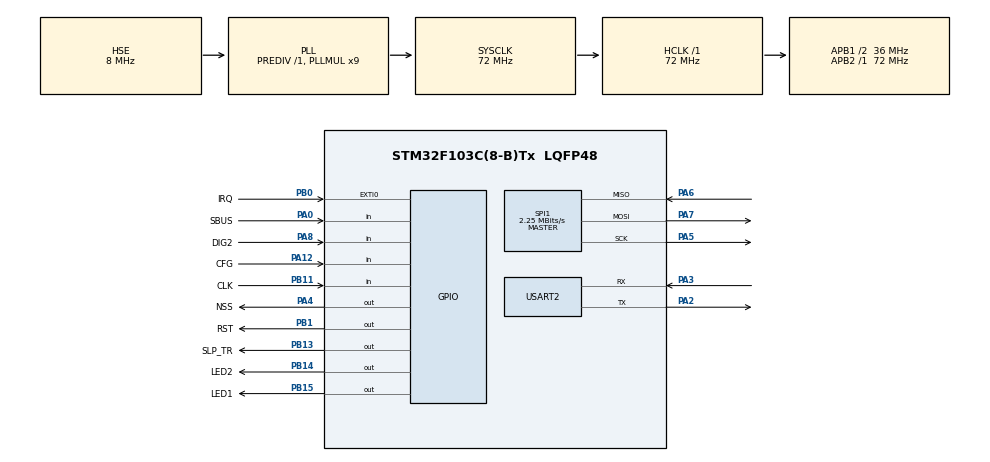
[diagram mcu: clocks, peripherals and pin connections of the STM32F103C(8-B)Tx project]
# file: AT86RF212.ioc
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Mcu.Family=STM32F1
Mcu.Name=STM32F103C(8-B)Tx
Mcu.Package=LQFP48
NVIC.PriorityGroup=NVIC_PRIORITYGROUP_4
NVIC.USART2_IRQn=true\:0\:0\:false\:false\:true\:true\:true
PA0-WKUP.GPIO_Label=SBUS
PA0-WKUP.GPIO_PuPd=GPIO_PULLUP
PA0-WKUP.Signal=GPIO_Input
PA12.GPIO_Label=CFG
PA12.GPIO_PuPd=GPIO_PULLUP
PA12.Signal=GPIO_Input
PA13.Mode=Serial_Wire
PA13.Signal=SYS_JTMS-SWDIO
PA14.Mode=Serial_Wire
PA14.Signal=SYS_JTCK-SWCLK
PA2.Mode=Asynchronous
PA2.Signal=USART2_TX
PA3.Mode=Asynchronous
PA3.Signal=USART2_RX
PA4.GPIO_Label=NSS
PA4.GPIO_PuPd=GPIO_PULLUP
PA4.GPIO_Speed=GPIO_SPEED_FREQ_MEDIUM
PA4.PinState=GPIO_PIN_SET
PA4.Signal=GPIO_Output
PA5.Mode=Full_Duplex_Master
PA5.Signal=SPI1_SCK
PA6.Mode=Full_Duplex_Master
PA6.Signal=SPI1_MISO
PA7.Mode=Full_Duplex_Master
PA7.Signal=SPI1_MOSI
PA8.GPIO_Label=DIG2
PA8.Signal=GPIO_Input
PB0.GPIO_Label=IRQ
PB0.GPIO_PuPd=GPIO_PULLUP
PB0.Signal=GPXTI0
PB1.GPIO_Label=RST
PB1.GPIO_ModeDefaultOutputPP=GPIO_MODE_OUTPUT_PP
PB1.GPIO_PuPd=GPIO_PULLUP
PB1.PinState=GPIO_PIN_SET
PB1.Signal=GPIO_Output
PB11.GPIO_Label=CLK
PB11.GPIO_PuPd=GPIO_PULLUP
PB11.Signal=GPIO_Input
PB13.GPIO_Label=SLP_TR
PB13.GPIO_PuPd=GPIO_NOPULL
PB13.GPIO_Speed=GPIO_SPEED_FREQ_MEDIUM
PB13.Signal=GPIO_Output
PB14.GPIO_Label=LED2
PB14.GPIO_PuPd=GPIO_PULLUP
PB14.GPIO_Speed=GPIO_SPEED_FREQ_LOW
PB14.PinState=GPIO_PIN_SET
PB14.Signal=GPIO_Output
PB15.GPIO_Label=LED1
PB15.GPIO_PuPd=GPIO_PULLUP
PB15.PinState=GPIO_PIN_SET
PB15.Signal=GPIO_Output
PD0-OSC_IN.Mode=HSE-External-Oscillator
PD0-OSC_IN.Signal=RCC_OSC_IN
PD1-OSC_OUT.Mode=HSE-External-Oscillator
PD1-OSC_OUT.Signal=RCC_OSC_OUT
ProjectManager.HeapSize=0x200
ProjectManager.StackSize=0x400
ProjectManager.TargetToolchain=MDK-ARM V5
RCC.AHBFreq_Value=72000000
RCC.APB1CLKDivider=RCC_HCLK_DIV2
RCC.APB1Freq_Value=36000000
RCC.APB1TimFreq_Value=72000000
RCC.APB2Freq_Value=72000000
RCC.APB2TimFreq_Value=72000000
RCC.HCLKFreq_Value=72000000
RCC.PLLMUL=RCC_PLL_MUL9
RCC.PLLSourceVirtual=RCC_PLLSOURCE_HSE
RCC.SYSCLKFreq_VALUE=72000000
RCC.SYSCLKSource=RCC_SYSCLKSOURCE_PLLCLK
RCC.USBFreq_Value=72000000
SPI1.BaudRatePrescaler=SPI_BAUDRATEPRESCALER_32
SPI1.CalculateBaudRate=2.25 MBits/s
SPI1.Direction=SPI_DIRECTION_2LINES
SPI1.Mode=SPI_MODE_MASTER
SPI1.VirtualType=VM_MASTER
USART2.VirtualMode=VM_ASYNC
board=custom

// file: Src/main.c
/* USER CODE BEGIN Header */
/**
  ******************************************************************************
  * @file           : main.c
  * @brief          : Main program body
  ******************************************************************************
  * @attention
  *
  * <h2><center>&copy; Copyright (c) 2019 STMicroelectronics.
  * All rights reserved.</center></h2>
  *
  * This software component is licensed by ST under BSD 3-Clause license,
  * the "License"; You may not use this file except in compliance with the
  * License. You may obtain a copy of the License at:
  *                        opensource.org/licenses/BSD-3-Clause
  *
  ******************************************************************************
  */
/* USER CODE END Header */

#include "main.h"
#include "spi.h"
#include "usart.h"
#include "gpio.h"

/* USER CODE BEGIN Includes */
#include "../Inc/MainController.h"
#include "../Settings/TerminalSettings.h"
/* USER CODE END Includes */

/* USER CODE BEGIN PV */
/* Private variables ---------------------------------------------------------*/

/* USER CODE END PV */

void SystemClock_Config(void);
/* USER CODE BEGIN PFP */
/* Private function prototypes -----------------------------------------------*/

/* USER CODE END PFP */

/* USER CODE BEGIN 0 */
uint8_t aRxBuffer1;      // 用来接收串口1发送的数据
/* USER CODE END 0 */

int main(void)
{

  /* MCU Configuration--------------------------------------------------------*/

  /* Reset of all peripherals, Initializes the Flash interface and the Systick. */
  HAL_Init();

  /* Configure the system clock */
  SystemClock_Config();

  /* Initialize all configured peripherals */
  MX_GPIO_Init();
  MX_SPI1_Init();
  MX_USART2_UART_Init();
  /* USER CODE BEGIN 2 */
  HAL_UART_Receive_IT(&huart2,&aRxBuffer1,1);          // Enable the USART2 Interrupt

  HAL_GPIO_WritePin(LED2_GPIO_Port, LED2_Pin, GPIO_PIN_SET);
  printf("systerm init ok . . .\r\n");

   MainControllerSetMode(MODE_RAW_RX_TX);

  /* USER CODE END 2 */

  /* Infinite loop */
  while (1)
  {

    /* USER CODE BEGIN 3 */
	MainControllerLoop();
	HAL_Delay(100);
	HAL_GPIO_TogglePin(GPIOB, LED1_Pin);
  }
  /* USER CODE END 3 */
}

void SystemClock_Config(void)
{
  RCC_OscInitTypeDef RCC_OscInitStruct = {0};
  RCC_ClkInitTypeDef RCC_ClkInitStruct = {0};

  /** Initializes the CPU, AHB and APB busses clocks
  */
  RCC_OscInitStruct.OscillatorType = RCC_OSCILLATORTYPE_HSE;
  RCC_OscInitStruct.HSEState = RCC_HSE_ON;
  RCC_OscInitStruct.HSEPredivValue = RCC_HSE_PREDIV_DIV1;
  RCC_OscInitStruct.HSIState = RCC_HSI_ON;
  RCC_OscInitStruct.PLL.PLLState = RCC_PLL_ON;
  RCC_OscInitStruct.PLL.PLLSource = RCC_PLLSOURCE_HSE;
  RCC_OscInitStruct.PLL.PLLMUL = RCC_PLL_MUL9;
  if (HAL_RCC_OscConfig(&RCC_OscInitStruct) != HAL_OK)
  {
    Error_Handler();
  }
  /** Initializes the CPU, AHB and APB busses clocks
  */
  RCC_ClkInitStruct.ClockType = RCC_CLOCKTYPE_HCLK|RCC_CLOCKTYPE_SYSCLK
                              |RCC_CLOCKTYPE_PCLK1|RCC_CLOCKTYPE_PCLK2;
  RCC_ClkInitStruct.SYSCLKSource = RCC_SYSCLKSOURCE_PLLCLK;
  RCC_ClkInitStruct.AHBCLKDivider = RCC_SYSCLK_DIV1;
  RCC_ClkInitStruct.APB1CLKDivider = RCC_HCLK_DIV2;
  RCC_ClkInitStruct.APB2CLKDivider = RCC_HCLK_DIV1;

  if (HAL_RCC_ClockConfig(&RCC_ClkInitStruct, FLASH_LATENCY_2) != HAL_OK)
  {
    Error_Handler();
  }
}

void Error_Handler(void)
{
  while(1)
  {
  }
}

/************************ (C) COPYRIGHT STMicroelectronics *****END OF FILE****/
